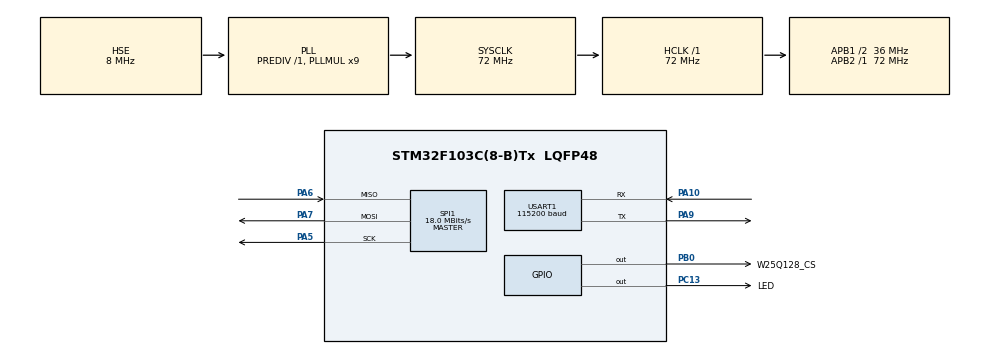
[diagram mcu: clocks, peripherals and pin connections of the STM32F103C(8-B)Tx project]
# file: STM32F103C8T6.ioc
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Dma.Request0=USART1_RX
Dma.USART1_RX.0.Direction=DMA_PERIPH_TO_MEMORY
Dma.USART1_RX.0.Instance=DMA1_Channel5
Dma.USART1_RX.0.MemDataAlignment=DMA_MDATAALIGN_BYTE
Dma.USART1_RX.0.MemInc=DMA_MINC_ENABLE
Dma.USART1_RX.0.Mode=DMA_NORMAL
Dma.USART1_RX.0.PeriphDataAlignment=DMA_PDATAALIGN_BYTE
Dma.USART1_RX.0.PeriphInc=DMA_PINC_DISABLE
Dma.USART1_RX.0.Priority=DMA_PRIORITY_LOW
Mcu.Family=STM32F1
Mcu.Name=STM32F103C(8-B)Tx
Mcu.Package=LQFP48
NVIC.DMA1_Channel5_IRQn=true\:0\:0\:false\:false\:true\:false\:true\:true
NVIC.PriorityGroup=NVIC_PRIORITYGROUP_4
NVIC.TIM3_IRQn=true\:0\:0\:false\:false\:true\:true\:true\:true
NVIC.USART1_IRQn=true\:0\:0\:false\:false\:true\:true\:true\:true
PA10.Mode=Asynchronous
PA10.Signal=USART1_RX
PA13.Mode=Serial_Wire
PA13.Signal=SYS_JTMS-SWDIO
PA14.Mode=Serial_Wire
PA14.Signal=SYS_JTCK-SWCLK
PA5.Mode=Full_Duplex_Master
PA5.Signal=SPI1_SCK
PA6.Mode=Full_Duplex_Master
PA6.Signal=SPI1_MISO
PA7.Mode=Full_Duplex_Master
PA7.Signal=SPI1_MOSI
PA9.Mode=Asynchronous
PA9.Signal=USART1_TX
PB0.GPIO_Label=W25Q128_CS
PB0.GPIO_ModeDefaultOutputPP=GPIO_MODE_OUTPUT_PP
PB0.GPIO_Speed=GPIO_SPEED_FREQ_HIGH
PB0.PinState=GPIO_PIN_SET
PB0.Signal=GPIO_Output
PC13-TAMPER-RTC.GPIO_Label=LED
PC13-TAMPER-RTC.GPIO_ModeDefaultOutputPP=GPIO_MODE_OUTPUT_PP
PC13-TAMPER-RTC.Signal=GPIO_Output
PD0-OSC_IN.Mode=HSE-External-Oscillator
PD0-OSC_IN.Signal=RCC_OSC_IN
PD1-OSC_OUT.Mode=HSE-External-Oscillator
PD1-OSC_OUT.Signal=RCC_OSC_OUT
ProjectManager.HeapSize=0x200
ProjectManager.StackSize=0x400
ProjectManager.TargetToolchain=MDK-ARM V5.27
RCC.ADCPresc=RCC_ADCPCLK2_DIV6
RCC.AHBFreq_Value=72000000
RCC.APB1CLKDivider=RCC_HCLK_DIV2
RCC.APB1Freq_Value=36000000
RCC.APB1TimFreq_Value=72000000
RCC.APB2Freq_Value=72000000
RCC.APB2TimFreq_Value=72000000
RCC.HCLKFreq_Value=72000000
RCC.PLLMUL=RCC_PLL_MUL9
RCC.PLLSourceVirtual=RCC_PLLSOURCE_HSE
RCC.SYSCLKFreq_VALUE=72000000
RCC.SYSCLKSource=RCC_SYSCLKSOURCE_PLLCLK
RCC.USBFreq_Value=72000000
SPI1.BaudRatePrescaler=SPI_BAUDRATEPRESCALER_4
SPI1.CLKPhase=SPI_PHASE_1EDGE
SPI1.CLKPolarity=SPI_POLARITY_LOW
SPI1.CalculateBaudRate=18.0 MBits/s
SPI1.Direction=SPI_DIRECTION_2LINES
SPI1.Mode=SPI_MODE_MASTER
SPI1.VirtualType=VM_MASTER
TIM2.Period=10000-1
TIM2.Prescaler=72-1
TIM3.Period=1000-1
TIM3.Prescaler=72-1
USART1.BaudRate=115200
USART1.Mode=MODE_TX_RX
USART1.OverSampling=UART_OVERSAMPLING_16
USART1.Parity=PARITY_NONE
USART1.StopBits=STOPBITS_1
USART1.VirtualMode=VM_ASYNC
USART1.WordLength=WORDLENGTH_8B
VP_TIM2_VS_ClockSourceINT.Mode=Internal
VP_TIM3_VS_ClockSourceINT.Mode=Internal
board=custom

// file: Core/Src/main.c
/* USER CODE BEGIN Header */
/**
  ******************************************************************************
  * @file           : main.c
  * @brief          : Main program body
  ******************************************************************************
  * @attention
  *
  * Copyright (c) 2023 STMicroelectronics.
  * All rights reserved.
  *
  * This software is licensed under terms that can be found in the LICENSE file
  * in the root directory of this software component.
  * If no LICENSE file comes with this software, it is provided AS-IS.
  *
  ******************************************************************************
  */
/* USER CODE END Header */
#include "main.h"
#include "dma.h"
#include "spi.h"
#include "tim.h"
#include "usart.h"
#include "gpio.h"

/* USER CODE BEGIN Includes */
#include "./W25Q128/w25q128.h"
/* USER CODE END Includes */

void SystemClock_Config(void);

int main(void)
{

  /* MCU Configuration--------------------------------------------------------*/

  /* Reset of all peripherals, Initializes the Flash interface and the Systick. */
  HAL_Init();

  /* Configure the system clock */
  SystemClock_Config();

  /* Initialize all configured peripherals */
  MX_GPIO_Init();
  MX_DMA_Init();
  MX_USART1_UART_Init();
  MX_TIM2_Init();
  MX_TIM3_Init();
  MX_SPI1_Init();
  /* USER CODE BEGIN 2 */

	W25QXX_Init();
	uint32_t size = 1000;
	uint8_t write_buf[1000];
	uint8_t read_buf[1000];		/* 设置栈大小2K不然会溢出*/

	for(uint16_t i=0; i<size; i++)
	{
		printf("write_buf[%d] = %d\r\n",i,i%256);
		write_buf[i] = i;
	}
	W25QXX_Write(write_buf, 0x000100, size);

	HAL_Delay(10);

	W25QXX_Read(read_buf, 0x000100, 1000);
	for(uint16_t i=0; i<1000; i++)
	{
		printf("read_buf[%d] = %d \r\n",i,read_buf[i]);
	}

  /* USER CODE END 2 */

  /* Infinite loop */
  while (1)
  {

  }
}

void SystemClock_Config(void)
{
  RCC_OscInitTypeDef RCC_OscInitStruct = {0};
  RCC_ClkInitTypeDef RCC_ClkInitStruct = {0};

  /** Initializes the RCC Oscillators according to the specified parameters
  * in the RCC_OscInitTypeDef structure.
  */
  RCC_OscInitStruct.OscillatorType = RCC_OSCILLATORTYPE_HSE;
  RCC_OscInitStruct.HSEState = RCC_HSE_ON;
  RCC_OscInitStruct.HSEPredivValue = RCC_HSE_PREDIV_DIV1;
  RCC_OscInitStruct.HSIState = RCC_HSI_ON;
  RCC_OscInitStruct.PLL.PLLState = RCC_PLL_ON;
  RCC_OscInitStruct.PLL.PLLSource = RCC_PLLSOURCE_HSE;
  RCC_OscInitStruct.PLL.PLLMUL = RCC_PLL_MUL9;
  if (HAL_RCC_OscConfig(&RCC_OscInitStruct) != HAL_OK)
  {
    Error_Handler();
  }

  /** Initializes the CPU, AHB and APB buses clocks
  */
  RCC_ClkInitStruct.ClockType = RCC_CLOCKTYPE_HCLK|RCC_CLOCKTYPE_SYSCLK
                              |RCC_CLOCKTYPE_PCLK1|RCC_CLOCKTYPE_PCLK2;
  RCC_ClkInitStruct.SYSCLKSource = RCC_SYSCLKSOURCE_PLLCLK;
  RCC_ClkInitStruct.AHBCLKDivider = RCC_SYSCLK_DIV1;
  RCC_ClkInitStruct.APB1CLKDivider = RCC_HCLK_DIV2;
  RCC_ClkInitStruct.APB2CLKDivider = RCC_HCLK_DIV1;

  if (HAL_RCC_ClockConfig(&RCC_ClkInitStruct, FLASH_LATENCY_2) != HAL_OK)
  {
    Error_Handler();
  }
}

void Error_Handler(void)
{
  __disable_irq();
  while (1)
  {
  }
}
